# clSOC register map
Vendor: litex
Registers are 32-bit, read-write, reset 0x0 unless marked. A register's access mark holds for its fields unless they carry their own. Offsets are from the block's base; [hi:lo] are bit positions; {n}, {i} and the like mark numbered series.

## SDRAM
Base 0xF0003000
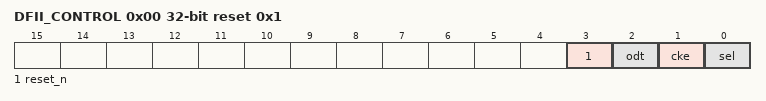
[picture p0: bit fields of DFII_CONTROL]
0x00 DFII_CONTROL reset 0x1
  [3] reset_n, [2] odt, [1] cke, [0] sel
0x04 DFII_PI0_COMMAND
  [5:0] dfii_pi0_command
0x08 DFII_PI0_COMMAND_ISSUE
  [0] dfii_pi0_command_issue
0x0C DFII_PI0_ADDRESS
  [10:0] dfii_pi0_address
0x10 DFII_PI0_BADDRESS
  [0] dfii_pi0_baddress
0x14 DFII_PI0_WRDATA
0x18 DFII_PI0_RDDATA

## SPIFLASH
Base 0xF0003800
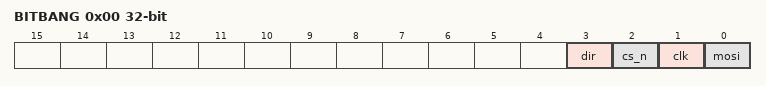
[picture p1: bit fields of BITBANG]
0x00 BITBANG — Bitbang controls for SPI output.
  [3] dir — Unused in this design.
  [2] cs_n — Output value for SPI CSn pin.
  [1] clk — Output value for SPI CLK pin.
  [0] mosi — Output value for SPI MOSI pin.
0x04 MISO — Incoming value of MISO pin.
  [0] miso
0x08 BITBANG_EN — Write a ``1`` here to disable memory-mapped mode and enable bitbang mode.
  [0] bitbang_en

## ETHPHY
Base 0xF0004000
0x00 CRG_RESET
  [0] crg_reset
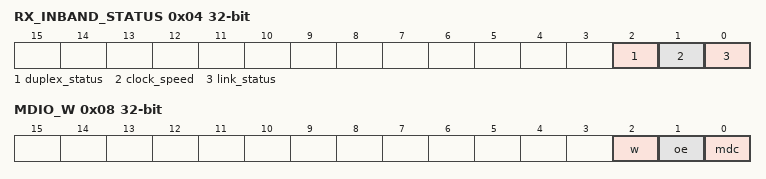
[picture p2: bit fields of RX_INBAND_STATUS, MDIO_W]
0x04 RX_INBAND_STATUS
  [2] duplex_status, [1] clock_speed, [0] link_status
0x08 MDIO_W
  [2] w, [1] oe, [0] mdc
0x0C MDIO_R
  [0] r

## ETHMAC
Base 0xF0004800
0x00 SRAM_WRITER_SLOT
  [0] sram_writer_slot
0x04 SRAM_WRITER_LENGTH
0x08 SRAM_WRITER_ERRORS
0x0C SRAM_WRITER_EV_STATUS — This register contains the current raw level of the available event trigger. Writes to this register have no effect.
  [0] available — Level of the ``available`` event
0x10 SRAM_WRITER_EV_PENDING — When a available event occurs, the corresponding bit will be set in this register. To clear the Event, set the corresponding bit in this register.
  [0] available — `1` if a `available` event occurred. This Event is **level triggered** when the signal is **high**.
0x14 SRAM_WRITER_EV_ENABLE — This register enables the corresponding available events. Write a ``0`` to this register to disable individual events.
  [0] available — Write a ``1`` to enable the ``available`` Event
0x18 SRAM_READER_START
  [0] sram_reader_start
0x1C SRAM_READER_READY
  [0] sram_reader_ready
0x20 SRAM_READER_LEVEL
  [1:0] sram_reader_level
0x24 SRAM_READER_SLOT
  [0] sram_reader_slot
0x28 SRAM_READER_LENGTH
  [10:0] sram_reader_length
0x2C SRAM_READER_EV_STATUS — This register contains the current raw level of the done event trigger. Writes to this register have no effect.
  [0] done — Level of the ``done`` event
0x30 SRAM_READER_EV_PENDING — When a done event occurs, the corresponding bit will be set in this register. To clear the Event, set the corresponding bit in this register.
  [0] done — `1` if a `done` event occurred. This Event is triggered on a **rising** edge.
0x34 SRAM_READER_EV_ENABLE — This register enables the corresponding done events. Write a ``0`` to this register to disable individual events.
  [0] done — Write a ``1`` to enable the ``done`` Event
0x38 PREAMBLE_CRC reset 0x1
  [0] preamble_crc
0x3C PREAMBLE_ERRORS
0x40 CRC_ERRORS

## LEDS
Base 0xF0005000
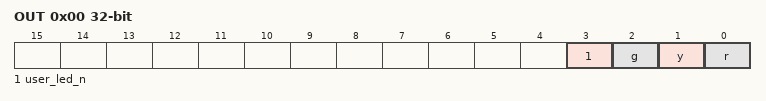
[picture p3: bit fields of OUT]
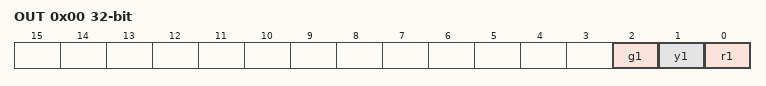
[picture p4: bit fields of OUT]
0x00 OUT
  [3] user_led_n — The onboard LED.
  [2] g — The Green Red LED.
  [1] y — The Yellow LED.
  [0] r — The Red LED.

## LEDS2
Base 0xF0005800
0x00 OUT
  [2] g1 — The second Green Red LED.
  [1] y1 — The second Yellow LED.
  [0] r1 — The second Red LED.

## GPIO
Base 0xF0006000
0x00 IN — GPIO Input(s) Status.
  [0] in
0x04 POLARITY — GPIO IRQ Polarity: 0: Rising Edge, 1: Falling Edge.
  [0] polarity
0x08 EV_STATUS — This register contains the current raw level of the i0 event trigger. Writes to this register have no effect.
  [0] i0 — Level of the ``i0`` event
0x0C EV_PENDING — When a i0 event occurs, the corresponding bit will be set in this register. To clear the Event, set the corresponding bit in this register.
  [0] i0 — `1` if a `i0` event occurred. This Event is triggered on a **falling** edge.
0x10 EV_ENABLE — This register enables the corresponding i0 events. Write a ``0`` to this register to disable individual events.
  [0] i0 — Write a ``1`` to enable the ``i0`` Event

## PWM
Base 0xF0007000
0x00 PERIOD — pwm period in sys cycles
0x04 VALUE — pwm output value in sys cycles

## ETHMEM
Base 0x80000000
{0x0+i} RX_BUFFER_0[{i}] (i=0..2047) 8-bit ro — rx buffers
  [7:0] rx_buffer_0
{0x800+i} RX_BUFFER_1[{i}] (i=0..2047) 8-bit ro — rx buffers
  [7:0] rx_buffer_1
{0x1000+i} TX_BUFFER_0[{i}] (i=0..2047) 8-bit — tx buffers
  [7:0] tx_buffer_0
{0x1800+i} TX_BUFFER_1[{i}] (i=0..2047) 8-bit — tx buffers
  [7:0] tx_buffer_1
